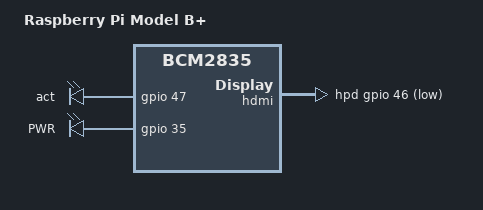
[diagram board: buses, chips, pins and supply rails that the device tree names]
/dts-v1/;
#include "bcm2835.dtsi"
#include "bcm2835-rpi.dtsi"
#include "bcm283x-rpi-smsc9514.dtsi"
#include "bcm283x-rpi-usb-host.dtsi"

/ {
	compatible = "raspberrypi,model-b-plus", "brcm,bcm2835";
	model = "Raspberry Pi Model B+";

	leds {
		act {
			gpios = <&gpio 47 0>;
		};

		pwr {
			label = "PWR";
			gpios = <&gpio 35 0>;
			default-state = "keep";
			linux,default-trigger = "default-on";
		};
	};
};

&gpio {
	/*
	 * Taken from Raspberry-Pi-B-Plus-V1.2-Schematics.pdf
	 * RPI-BPLUS sheet 1
	 *
	 * Legend:
	 * "NC" = not connected (no rail from the SoC)
	 * "[FOO]" = pin is muxed for peripheral FOO (not GPIO)
	 * "FOO" = GPIO line named "FOO" on the schematic
	 * "FOO_N" = GPIO line named "FOO" on schematic, active low
	 */
	gpio-line-names = "[ID_SD]",
			  "[ID_SC]",
			  "[P3_SDA1]",
			  "[P5_SCL1]",
			  "[P7_GPIO_GCLK]",
			  "P29_GPIO5",
			  "P31_GPIO6",
			  "[P26_SPI_CE1_N]",
			  "[P24_SPI_CE0_N]",
			  "[P21_SPI_MISO]",
			  "[P19_SPI_MOSI]",
			  "[P23_SPI_SCLK]",
			  "P23_GPIO12",
			  "P33_GPIO13",
			  /* Serial port */
			  "[P8_TXD0]",
			  "[P10_RXD0]",
			  "P36_GPIO16",
			  "P11_GPIO17",
			  "P12_GPIO18",
			  "P35_GPIO19",
			  "P38_GPIO20",
			  "P40_GPIO21",
			  "P15_GPIO22",
			  "P16_GPIO23",
			  "P18_GPIO24",
			  "P22_GPIO25",
			  "P37_GPIO26",
			  "P13_GPIO27",
			  "[SDA0]",
			  "[SCL0]",
			  "NC", /* GPIO30 */
			  "LAN_RUN", /* GPIO31 */
			  "CAM_GPIO1", /* GPIO32 */
			  "NC", /* GPIO33 */
			  "NC", /* GPIO34 */
			  "PWR_LOW_N", /* GPIO35 */
			  "NC", /* GPIO36 */
			  "NC", /* GPIO37 */
			  "NC", /* GPIO38 */
			  "NC", /* GPIO39 */
			  "[PWM0_OUT]", /* GPIO40 */
			  "CAM_GPIO0", /* GPIO41 */
			  "NC", /* GPIO42 */
			  "NC", /* GPIO43 */
			  "ETHCLK", /* GPIO44 */
			  "[PWM1_OUT]", /* GPIO45 */
			  "HDMI_HPD_N",
			  "STATUS_LED",
			  /* Used by SD Card */
			  "[SD_CLK_R]",
			  "[SD_CMD_R]",
			  "[SD_DATA0_R]",
			  "[SD_DATA1_R]",
			  "[SD_DATA2_R]",
			  "[SD_DATA3_R]";

	pinctrl-0 = <&gpioout &alt0 &i2s_alt0>;

	/* I2S interface */
	i2s_alt0: i2s_alt0 {
		brcm,pins = <18 19 20 21>;
		brcm,function = <BCM2835_FSEL_ALT0>;
	};
};

&hdmi {
	hpd-gpios = <&gpio 46 GPIO_ACTIVE_LOW>;
};
